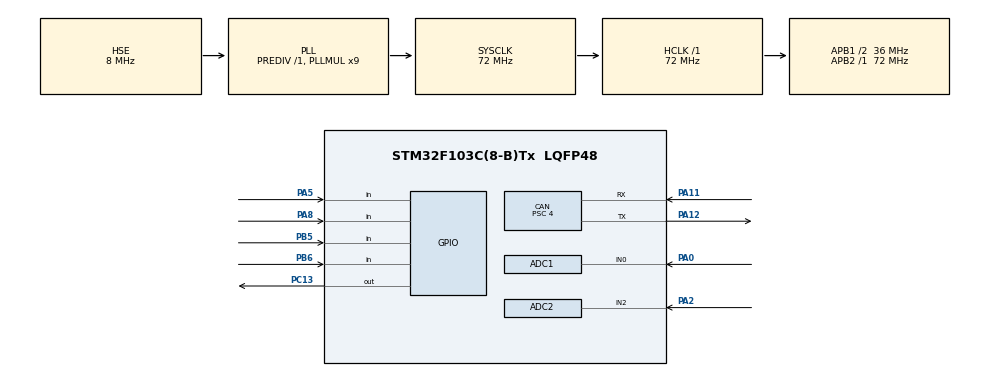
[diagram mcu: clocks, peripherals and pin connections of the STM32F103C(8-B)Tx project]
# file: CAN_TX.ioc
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ADC1.Channel-2\#ChannelRegularConversion=ADC_CHANNEL_0
ADC1.ContinuousConvMode=DISABLE
ADC1.EnableRegularConversion=ENABLE
ADC1.NbrOfConversionFlag=1
ADC1.Rank-2\#ChannelRegularConversion=1
ADC1.SamplingTime-2\#ChannelRegularConversion=ADC_SAMPLETIME_1CYCLE_5
ADC1.master=1
ADC2.Channel-1\#ChannelRegularConversion=ADC_CHANNEL_2
ADC2.ContinuousConvMode=ENABLE
ADC2.EnableRegularConversion=ENABLE
ADC2.NbrOfConversionFlag=1
ADC2.Rank-1\#ChannelRegularConversion=1
ADC2.SamplingTime-1\#ChannelRegularConversion=ADC_SAMPLETIME_1CYCLE_5
CAN.ABOM=ENABLE
CAN.AWUM=ENABLE
CAN.BS1=CAN_BS1_13TQ
CAN.BS2=CAN_BS2_4TQ
CAN.CalculateBaudRate=500000
CAN.CalculateTimeBit=2000
CAN.CalculateTimeQuantum=111.11111111111111
CAN.Prescaler=4
CAN.TXFP=ENABLE
Mcu.Family=STM32F1
Mcu.Name=STM32F103C(8-B)Tx
Mcu.Package=LQFP48
NVIC.PriorityGroup=NVIC_PRIORITYGROUP_4
PA0-WKUP.Signal=ADCx_IN0
PA11.Mode=CAN_Activate
PA11.Signal=CAN_RX
PA12.Mode=CAN_Activate
PA12.Signal=CAN_TX
PA13.Mode=Serial_Wire
PA13.Signal=SYS_JTMS-SWDIO
PA14.Mode=Serial_Wire
PA14.Signal=SYS_JTCK-SWCLK
PA2.Signal=ADCx_IN2
PA5.GPIO_PuPd=GPIO_PULLDOWN
PA5.Signal=GPIO_Input
PA8.GPIO_PuPd=GPIO_PULLDOWN
PA8.Signal=GPIO_Input
PB5.GPIO_PuPd=GPIO_PULLDOWN
PB5.Signal=GPIO_Input
PB6.GPIO_PuPd=GPIO_PULLDOWN
PB6.Signal=GPIO_Input
PC13-TAMPER-RTC.Signal=GPIO_Output
PD0-OSC_IN.Mode=HSE-External-Oscillator
PD0-OSC_IN.Signal=RCC_OSC_IN
PD1-OSC_OUT.Mode=HSE-External-Oscillator
PD1-OSC_OUT.Signal=RCC_OSC_OUT
ProjectManager.HeapSize=0x200
ProjectManager.StackSize=0x400
ProjectManager.TargetToolchain=MDK-ARM V5.32
RCC.ADCPresc=RCC_ADCPCLK2_DIV6
RCC.AHBFreq_Value=72000000
RCC.APB1CLKDivider=RCC_HCLK_DIV2
RCC.APB1Freq_Value=36000000
RCC.APB1TimFreq_Value=72000000
RCC.APB2Freq_Value=72000000
RCC.APB2TimFreq_Value=72000000
RCC.HCLKFreq_Value=72000000
RCC.PLLMUL=RCC_PLL_MUL9
RCC.PLLSourceVirtual=RCC_PLLSOURCE_HSE
RCC.SYSCLKFreq_VALUE=72000000
RCC.SYSCLKSource=RCC_SYSCLKSOURCE_PLLCLK
RCC.USBFreq_Value=72000000
SH.ADCx_IN0.0=ADC1_IN0,IN0
SH.ADCx_IN2.0=ADC2_IN2,IN2
board=custom

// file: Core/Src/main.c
/* USER CODE BEGIN Header */
/**
  ******************************************************************************
  * @file           : main.c
  * @brief          : Main program body
  ******************************************************************************
  * @attention
  *
  * Copyright (c) 2025 STMicroelectronics.
  * All rights reserved.
  *
  * This software is licensed under terms that can be found in the LICENSE file
  * in the root directory of this software component.
  * If no LICENSE file comes with this software, it is provided AS-IS.
  *
  ******************************************************************************
  */
/* USER CODE END Header */
#include "main.h"

ADC_HandleTypeDef hadc1;
ADC_HandleTypeDef hadc2;

CAN_HandleTypeDef hcan;

void SystemClock_Config(void);
static void MX_GPIO_Init(void);
static void MX_CAN_Init(void);
static void MX_ADC1_Init(void);
static void MX_ADC2_Init(void);

/* USER CODE BEGIN 0 */
uint32_t adc_nhietdoPin;
uint32_t adc_luongPin;
uint8_t TxData_info[8];
uint8_t TxDKDC[8];
float temperaturePin;
float Vbat;
/* USER CODE END 0 */

int main(void)
{

  /* MCU Configuration--------------------------------------------------------*/

  /* Reset of all peripherals, Initializes the Flash interface and the Systick. */
  HAL_Init();

  /* Configure the system clock */
  SystemClock_Config();

  /* Initialize all configured peripherals */
  MX_GPIO_Init();
  MX_CAN_Init();
  MX_ADC1_Init();
  MX_ADC2_Init();
  /* USER CODE BEGIN 2 */
HAL_CAN_Start(&hcan);
  CAN_FilterTypeDef filterConfig;
  filterConfig.FilterActivation = ENABLE;
  filterConfig.FilterBank = 0;
  filterConfig.FilterFIFOAssignment = CAN_FILTER_FIFO0;
  filterConfig.FilterIdHigh = 0x123 << 5;
  filterConfig.FilterIdLow = 0x0000;
  filterConfig.FilterMaskIdHigh = 0xFFE0;
  filterConfig.FilterMaskIdLow = 0x0000;
  filterConfig.FilterMode = CAN_FILTERMODE_IDMASK;
  filterConfig.FilterScale = CAN_FILTERSCALE_32BIT;

  HAL_CAN_ConfigFilter(&hcan, &filterConfig);

	CAN_TxHeaderTypeDef TxHeader;
uint32_t TxMailbox;

TxHeader.StdId = 0x202;
TxHeader.IDE = CAN_ID_STD;
TxHeader.RTR = CAN_RTR_DATA;
TxHeader.DLC = 8;
CAN_TxHeaderTypeDef Txdkdc;
Txdkdc.StdId = 0x301;
Txdkdc. IDE = CAN_ID_STD;
Txdkdc.RTR= CAN_RTR_DATA;
Txdkdc.DLC = 8;

typedef struct {
    uint16_t VPin_adc;      // 2 byte
    uint16_t temperature_adc;  // 2 byte
    uint8_t headlight;         // 1 bit
    uint8_t turn_left;         // 1 bit
    uint8_t turn_right;        // 1 bit
		uint8_t brake; 						//  1 bit
} CAN_DataFrame_t;
CAN_DataFrame_t canData;
  /* USER CODE END 2 */

  /* Infinite loop */
  while (1)
  {

    /* USER CODE BEGIN 3 */

		 HAL_ADC_Start(&hadc1);
    HAL_ADC_PollForConversion(&hadc1, 10);
    adc_luongPin = HAL_ADC_GetValue(&hadc1);
    HAL_ADC_Stop(&hadc1);
		HAL_ADC_Start(&hadc2);
	HAL_ADC_PollForConversion(&hadc2,10);
	adc_nhietdoPin = HAL_ADC_GetValue(&hadc2);
		HAL_ADC_Stop(&hadc2);

		// Gán giá tr? ADC
	float temperature = (adc_nhietdoPin / 4095.0f) * 800.0f;  // don v? tùy ch?n (°C, ho?c 0–800 n?i suy)
	float Vbat = (adc_luongPin / 4095.0f) * 600.0f;
canData.VPin_adc = Vbat;
canData.temperature_adc = temperature;

// Gi? s? b?n dang d?c tr?ng thái dèn/giao thông t? GPIO
canData.headlight = HAL_GPIO_ReadPin(GPIOA, GPIO_PIN_7);
canData.turn_left = HAL_GPIO_ReadPin(GPIOB, GPIO_PIN_5);
canData.turn_right = HAL_GPIO_ReadPin(GPIOB, GPIO_PIN_6);
canData.brake = HAL_GPIO_ReadPin(GPIOA, GPIO_PIN_8);  // Ð?c chân phanh

// Gói d? li?u vào TxData[]
TxData_info[0] = (canData.VPin_adc >> 8) & 0xFF;
TxData_info[1] = canData.VPin_adc & 0xFF;

TxData_info[2] = (canData.temperature_adc >> 8) & 0xFF;
TxData_info[3] = canData.temperature_adc & 0xFF;

// Byte 4: 1 bit headlight, 1 bit turn_left, 1 bit turn_right, 5 bit reserved
TxData_info[4] = (canData.headlight & 0x01) << 7 |
            (canData.turn_left & 0x01) << 6 |
            (canData.turn_right & 0x01) << 5| // còn l?i 5 bit = 0
						(canData.brake    & 0x01) << 4;   // Thêm brake vào bit 4
// Các byte còn l?i (5–7) d? padding ho?c m? r?ng sau này
TxData_info[5] = 0;
TxData_info[6] = 0;
TxData_info[7] = 0;

TxDKDC[0] = (canData.VPin_adc >> 8) & 0xFF;
TxDKDC[1] = canData.VPin_adc & 0xFF;

TxDKDC[2] = (canData.temperature_adc >> 8) & 0xFF;
TxDKDC[3] = canData.temperature_adc & 0xFF;

TxDKDC[4] = (canData.brake & 0x01) << 7;  // d?t ? bit 7 (MSB)
TxDKDC[5] = 0;
TxDKDC[6] = 0;
TxDKDC[7] = 0;
HAL_CAN_AddTxMessage(&hcan, &Txdkdc, TxDKDC, &TxMailbox);
HAL_Delay(100);
// G?i CAN
HAL_CAN_AddTxMessage(&hcan, &TxHeader, TxData_info, &TxMailbox);
HAL_Delay(100); // g?i m?i 100ms
if (HAL_CAN_AddTxMessage(&hcan, &TxHeader, TxData_info, &TxMailbox) != HAL_OK) {
    Error_Handler();
}

}
  /* USER CODE END 3 */
}

void SystemClock_Config(void)
{
  RCC_OscInitTypeDef RCC_OscInitStruct = {0};
  RCC_ClkInitTypeDef RCC_ClkInitStruct = {0};
  RCC_PeriphCLKInitTypeDef PeriphClkInit = {0};

  /** Initializes the RCC Oscillators according to the specified parameters
  * in the RCC_OscInitTypeDef structure.
  */
  RCC_OscInitStruct.OscillatorType = RCC_OSCILLATORTYPE_HSE;
  RCC_OscInitStruct.HSEState = RCC_HSE_ON;
  RCC_OscInitStruct.HSEPredivValue = RCC_HSE_PREDIV_DIV1;
  RCC_OscInitStruct.HSIState = RCC_HSI_ON;
  RCC_OscInitStruct.PLL.PLLState = RCC_PLL_ON;
  RCC_OscInitStruct.PLL.PLLSource = RCC_PLLSOURCE_HSE;
  RCC_OscInitStruct.PLL.PLLMUL = RCC_PLL_MUL9;
  if (HAL_RCC_OscConfig(&RCC_OscInitStruct) != HAL_OK)
  {
    Error_Handler();
  }

  /** Initializes the CPU, AHB and APB buses clocks
  */
  RCC_ClkInitStruct.ClockType = RCC_CLOCKTYPE_HCLK|RCC_CLOCKTYPE_SYSCLK
                              |RCC_CLOCKTYPE_PCLK1|RCC_CLOCKTYPE_PCLK2;
  RCC_ClkInitStruct.SYSCLKSource = RCC_SYSCLKSOURCE_PLLCLK;
  RCC_ClkInitStruct.AHBCLKDivider = RCC_SYSCLK_DIV1;
  RCC_ClkInitStruct.APB1CLKDivider = RCC_HCLK_DIV2;
  RCC_ClkInitStruct.APB2CLKDivider = RCC_HCLK_DIV1;

  if (HAL_RCC_ClockConfig(&RCC_ClkInitStruct, FLASH_LATENCY_2) != HAL_OK)
  {
    Error_Handler();
  }
  PeriphClkInit.PeriphClockSelection = RCC_PERIPHCLK_ADC;
  PeriphClkInit.AdcClockSelection = RCC_ADCPCLK2_DIV6;
  if (HAL_RCCEx_PeriphCLKConfig(&PeriphClkInit) != HAL_OK)
  {
    Error_Handler();
  }
}

static void MX_ADC1_Init(void)
{

  ADC_ChannelConfTypeDef sConfig = {0};

  /** Common config
  */
  hadc1.Instance = ADC1;
  hadc1.Init.ScanConvMode = ADC_SCAN_DISABLE;
  hadc1.Init.ContinuousConvMode = DISABLE;
  hadc1.Init.DiscontinuousConvMode = DISABLE;
  hadc1.Init.ExternalTrigConv = ADC_SOFTWARE_START;
  hadc1.Init.DataAlign = ADC_DATAALIGN_RIGHT;
  hadc1.Init.NbrOfConversion = 1;
  if (HAL_ADC_Init(&hadc1) != HAL_OK)
  {
    Error_Handler();
  }

  /** Configure Regular Channel
  */
  sConfig.Channel = ADC_CHANNEL_0;
  sConfig.Rank = ADC_REGULAR_RANK_1;
  sConfig.SamplingTime = ADC_SAMPLETIME_1CYCLE_5;
  if (HAL_ADC_ConfigChannel(&hadc1, &sConfig) != HAL_OK)
  {
    Error_Handler();
  }

}

static void MX_ADC2_Init(void)
{

  ADC_ChannelConfTypeDef sConfig = {0};

  /** Common config
  */
  hadc2.Instance = ADC2;
  hadc2.Init.ScanConvMode = ADC_SCAN_DISABLE;
  hadc2.Init.ContinuousConvMode = ENABLE;
  hadc2.Init.DiscontinuousConvMode = DISABLE;
  hadc2.Init.ExternalTrigConv = ADC_SOFTWARE_START;
  hadc2.Init.DataAlign = ADC_DATAALIGN_RIGHT;
  hadc2.Init.NbrOfConversion = 1;
  if (HAL_ADC_Init(&hadc2) != HAL_OK)
  {
    Error_Handler();
  }

  /** Configure Regular Channel
  */
  sConfig.Channel = ADC_CHANNEL_2;
  sConfig.Rank = ADC_REGULAR_RANK_1;
  sConfig.SamplingTime = ADC_SAMPLETIME_1CYCLE_5;
  if (HAL_ADC_ConfigChannel(&hadc2, &sConfig) != HAL_OK)
  {
    Error_Handler();
  }

}

static void MX_CAN_Init(void)
{

  hcan.Instance = CAN1;
  hcan.Init.Prescaler = 4;
  hcan.Init.Mode = CAN_MODE_NORMAL;
  hcan.Init.SyncJumpWidth = CAN_SJW_1TQ;
  hcan.Init.TimeSeg1 = CAN_BS1_13TQ;
  hcan.Init.TimeSeg2 = CAN_BS2_4TQ;
  hcan.Init.TimeTriggeredMode = DISABLE;
  hcan.Init.AutoBusOff = ENABLE;
  hcan.Init.AutoWakeUp = ENABLE;
  hcan.Init.AutoRetransmission = DISABLE;
  hcan.Init.ReceiveFifoLocked = DISABLE;
  hcan.Init.TransmitFifoPriority = ENABLE;
  if (HAL_CAN_Init(&hcan) != HAL_OK)
  {
    Error_Handler();
  }

}

static void MX_GPIO_Init(void)
{
  GPIO_InitTypeDef GPIO_InitStruct = {0};

  /* GPIO Ports Clock Enable */
  __HAL_RCC_GPIOC_CLK_ENABLE();
  __HAL_RCC_GPIOD_CLK_ENABLE();
  __HAL_RCC_GPIOA_CLK_ENABLE();
  __HAL_RCC_GPIOB_CLK_ENABLE();

  /*Configure GPIO pin Output Level */
  HAL_GPIO_WritePin(GPIOC, GPIO_PIN_13, GPIO_PIN_RESET);

  /*Configure GPIO pin : PC13 */
  GPIO_InitStruct.Pin = GPIO_PIN_13;
  GPIO_InitStruct.Mode = GPIO_MODE_OUTPUT_PP;
  GPIO_InitStruct.Pull = GPIO_NOPULL;
  GPIO_InitStruct.Speed = GPIO_SPEED_FREQ_LOW;
  HAL_GPIO_Init(GPIOC, &GPIO_InitStruct);

  /*Configure GPIO pins : PA5 PA8 */
  GPIO_InitStruct.Pin = GPIO_PIN_7|GPIO_PIN_8;
  GPIO_InitStruct.Mode = GPIO_MODE_INPUT;
  GPIO_InitStruct.Pull = GPIO_PULLDOWN;
  HAL_GPIO_Init(GPIOA, &GPIO_InitStruct);

  /*Configure GPIO pins : PB5 PB6 */
  GPIO_InitStruct.Pin = GPIO_PIN_5|GPIO_PIN_6;
  GPIO_InitStruct.Mode = GPIO_MODE_INPUT;
  GPIO_InitStruct.Pull = GPIO_PULLDOWN;
  HAL_GPIO_Init(GPIOB, &GPIO_InitStruct);

}

void Error_Handler(void)
{
  __disable_irq();
  while (1)
  {
  }
}
